AUTOSAR XML (schema 4-0-3)
package /Svc_NvM
  4 x impl type:
    NvM_BlockIdType: implementation-data-type=uint16
    NvM_RequestResultType: compu {0=NVM_REQ_OK, 1=NVM_REQ_NOT_OK, 2=NVM_REQ_PENDING, 3=NVM_REQ_INTEGRITY_FAILED, 4=NVM_REQ_BLOCK_SKIPPED, 5=NVM_REQ_NV_INVALIDATED, 6=NVM_REQ_CANCELED, 7=NVM_REQ_REDUNDANCY_FAILED, 8=NVM_REQ_RESTORED_FROM_ROM, 9=NVM_MAXVALUE}, implementation-data-type=uint8
    VoidPtr: category=DATA_REFERENCE, sw-pointer-target-props={target-category=VALUE, base-type=void}
    ConstVoidPtr: category=DATA_REFERENCE, sw-pointer-target-props={target-category=VALUE, base-type=void, sw-impl-policy=CONST}
  client server interface NvMNotifyInitBlock: is-service=true, service-kind=NON-VOLATILE-RAM-MANAGER
    operation InitBlock
  client server interface NvMNotifyJobFinished: is-service=true, service-kind=NON-VOLATILE-RAM-MANAGER
    operation JobFinished
      arg ServiceId: type=uint8, direction=IN
      arg JobResult: type=NvM_RequestResultType, direction=IN
  client server interface NvMService: is-service=true, service-kind=NON-VOLATILE-RAM-MANAGER
    7 x operation, all with possible-error=E_NOT_OK:
      GetErrorStatus
        arg RequestResultPtr: type=NvM_RequestResultType, direction=OUT
      ReadBlock
        arg Destination: type=VoidPtr, direction=IN
      WriteBlock
        arg Source: type=ConstVoidPtr, direction=IN
      RestoreBlockDefaults
        arg DstPtr: type=VoidPtr, direction=IN
      CancelJobs
      EraseNvBlock
      InvalidateNvBlock
    error E_NOT_OK: error-code=1
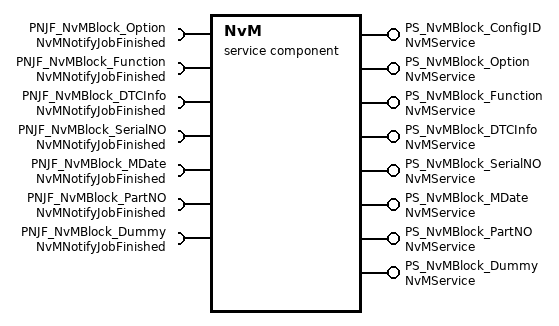
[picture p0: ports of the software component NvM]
  service sw component type NvM
    provide port PS_NvMBlock_ConfigID: provided-interface=NvMService
      provided-com-specs:
        operation=CancelJobs, queue-length=1
        operation=EraseNvBlock, queue-length=1
        operation=GetErrorStatus, queue-length=1
        operation=InvalidateNvBlock, queue-length=1
        operation=ReadBlock, queue-length=1
        operation=RestoreBlockDefaults, queue-length=1
        operation=WriteBlock, queue-length=1
    provide port PS_NvMBlock_Option: provided-interface=NvMService
      provided-com-specs:
        operation=CancelJobs, queue-length=1
        operation=EraseNvBlock, queue-length=1
        operation=GetErrorStatus, queue-length=1
        operation=InvalidateNvBlock, queue-length=1
        operation=ReadBlock, queue-length=1
        operation=RestoreBlockDefaults, queue-length=1
        operation=WriteBlock, queue-length=1
    require port PNJF_NvMBlock_Option: client-com-spec=JobFinished, required-interface=NvMNotifyJobFinished
    provide port PS_NvMBlock_Function: provided-interface=NvMService
      provided-com-specs:
        operation=CancelJobs, queue-length=1
        operation=EraseNvBlock, queue-length=1
        operation=GetErrorStatus, queue-length=1
        operation=InvalidateNvBlock, queue-length=1
        operation=ReadBlock, queue-length=1
        operation=RestoreBlockDefaults, queue-length=1
        operation=WriteBlock, queue-length=1
    require port PNJF_NvMBlock_Function: client-com-spec=JobFinished, required-interface=NvMNotifyJobFinished
    provide port PS_NvMBlock_DTCInfo: provided-interface=NvMService
      provided-com-specs:
        operation=CancelJobs, queue-length=1
        operation=EraseNvBlock, queue-length=1
        operation=GetErrorStatus, queue-length=1
        operation=InvalidateNvBlock, queue-length=1
        operation=ReadBlock, queue-length=1
        operation=RestoreBlockDefaults, queue-length=1
        operation=WriteBlock, queue-length=1
    require port PNJF_NvMBlock_DTCInfo: client-com-spec=JobFinished, required-interface=NvMNotifyJobFinished
    provide port PS_NvMBlock_SerialNO: provided-interface=NvMService
      provided-com-specs:
        operation=CancelJobs, queue-length=1
        operation=EraseNvBlock, queue-length=1
        operation=GetErrorStatus, queue-length=1
        operation=InvalidateNvBlock, queue-length=1
        operation=ReadBlock, queue-length=1
        operation=RestoreBlockDefaults, queue-length=1
        operation=WriteBlock, queue-length=1
    require port PNJF_NvMBlock_SerialNO: client-com-spec=JobFinished, required-interface=NvMNotifyJobFinished
    provide port PS_NvMBlock_MDate: provided-interface=NvMService
      provided-com-specs:
        operation=CancelJobs, queue-length=1
        operation=EraseNvBlock, queue-length=1
        operation=GetErrorStatus, queue-length=1
        operation=InvalidateNvBlock, queue-length=1
        operation=ReadBlock, queue-length=1
        operation=RestoreBlockDefaults, queue-length=1
        operation=WriteBlock, queue-length=1
    require port PNJF_NvMBlock_MDate: client-com-spec=JobFinished, required-interface=NvMNotifyJobFinished
    provide port PS_NvMBlock_PartNO: provided-interface=NvMService
      provided-com-specs:
        operation=CancelJobs, queue-length=1
        operation=EraseNvBlock, queue-length=1
        operation=GetErrorStatus, queue-length=1
        operation=InvalidateNvBlock, queue-length=1
        operation=ReadBlock, queue-length=1
        operation=RestoreBlockDefaults, queue-length=1
        operation=WriteBlock, queue-length=1
    require port PNJF_NvMBlock_PartNO: client-com-spec=JobFinished, required-interface=NvMNotifyJobFinished
    provide port PS_NvMBlock_Dummy: provided-interface=NvMService
      provided-com-specs:
        operation=CancelJobs, queue-length=1
        operation=EraseNvBlock, queue-length=1
        operation=GetErrorStatus, queue-length=1
        operation=InvalidateNvBlock, queue-length=1
        operation=ReadBlock, queue-length=1
        operation=RestoreBlockDefaults, queue-length=1
        operation=WriteBlock, queue-length=1
    require port PNJF_NvMBlock_Dummy: client-com-spec=JobFinished, required-interface=NvMNotifyJobFinished
    behavior IB_NvM: handle-termination-and-restart=NO-SUPPORT
      56 x operation invoked event:
        OperationInvokedEvent_PS_NvMBlock_ConfigID_CancelJobs: start-on-event=CancelJobs, operation=PS_NvMBlock_ConfigID.CancelJobs
        OperationInvokedEvent_PS_NvMBlock_ConfigID_EraseNvBlock: start-on-event=EraseNvBlock, operation=PS_NvMBlock_ConfigID.EraseNvBlock
        OperationInvokedEvent_PS_NvMBlock_ConfigID_GetErrorStatus: start-on-event=GetErrorStatus, operation=PS_NvMBlock_ConfigID.GetErrorStatus
        OperationInvokedEvent_PS_NvMBlock_ConfigID_InvalidateNvBlock: start-on-event=InvalidateNvBlock, operation=PS_NvMBlock_ConfigID.InvalidateNvBlock
        OperationInvokedEvent_PS_NvMBlock_ConfigID_ReadBlock: start-on-event=ReadBlock, operation=PS_NvMBlock_ConfigID.ReadBlock
        OperationInvokedEvent_PS_NvMBlock_ConfigID_RestoreBlockDefaults: start-on-event=RestoreBlockDefaults, operation=PS_NvMBlock_ConfigID.RestoreBlockDefaults
        OperationInvokedEvent_PS_NvMBlock_ConfigID_WriteBlock: start-on-event=WriteBlock, operation=PS_NvMBlock_ConfigID.WriteBlock
        OperationInvokedEvent_PS_NvMBlock_Option_CancelJobs: start-on-event=CancelJobs, operation=PS_NvMBlock_Option.CancelJobs
        OperationInvokedEvent_PS_NvMBlock_Option_EraseNvBlock: start-on-event=EraseNvBlock, operation=PS_NvMBlock_Option.EraseNvBlock
        OperationInvokedEvent_PS_NvMBlock_Option_GetErrorStatus: start-on-event=GetErrorStatus, operation=PS_NvMBlock_Option.GetErrorStatus
        OperationInvokedEvent_PS_NvMBlock_Option_InvalidateNvBlock: start-on-event=InvalidateNvBlock, operation=PS_NvMBlock_Option.InvalidateNvBlock
        OperationInvokedEvent_PS_NvMBlock_Option_ReadBlock: start-on-event=ReadBlock, operation=PS_NvMBlock_Option.ReadBlock
        OperationInvokedEvent_PS_NvMBlock_Option_RestoreBlockDefaults: start-on-event=RestoreBlockDefaults, operation=PS_NvMBlock_Option.RestoreBlockDefaults
        OperationInvokedEvent_PS_NvMBlock_Option_WriteBlock: start-on-event=WriteBlock, operation=PS_NvMBlock_Option.WriteBlock
        OperationInvokedEvent_PS_NvMBlock_Function_CancelJobs: start-on-event=CancelJobs, operation=PS_NvMBlock_Function.CancelJobs
        OperationInvokedEvent_PS_NvMBlock_Function_EraseNvBlock: start-on-event=EraseNvBlock, operation=PS_NvMBlock_Function.EraseNvBlock
        OperationInvokedEvent_PS_NvMBlock_Function_GetErrorStatus: start-on-event=GetErrorStatus, operation=PS_NvMBlock_Function.GetErrorStatus
        OperationInvokedEvent_PS_NvMBlock_Function_InvalidateNvBlock: start-on-event=InvalidateNvBlock, operation=PS_NvMBlock_Function.InvalidateNvBlock
        OperationInvokedEvent_PS_NvMBlock_Function_ReadBlock: start-on-event=ReadBlock, operation=PS_NvMBlock_Function.ReadBlock
        OperationInvokedEvent_PS_NvMBlock_Function_RestoreBlockDefaults: start-on-event=RestoreBlockDefaults, operation=PS_NvMBlock_Function.RestoreBlockDefaults
        OperationInvokedEvent_PS_NvMBlock_Function_WriteBlock: start-on-event=WriteBlock, operation=PS_NvMBlock_Function.WriteBlock
        OperationInvokedEvent_PS_NvMBlock_DTCInfo_CancelJobs: start-on-event=CancelJobs, operation=PS_NvMBlock_DTCInfo.CancelJobs
        OperationInvokedEvent_PS_NvMBlock_DTCInfo_EraseNvBlock: start-on-event=EraseNvBlock, operation=PS_NvMBlock_DTCInfo.EraseNvBlock
        OperationInvokedEvent_PS_NvMBlock_DTCInfo_GetErrorStatus: start-on-event=GetErrorStatus, operation=PS_NvMBlock_DTCInfo.GetErrorStatus
        OperationInvokedEvent_PS_NvMBlock_DTCInfo_InvalidateNvBlock: start-on-event=InvalidateNvBlock, operation=PS_NvMBlock_DTCInfo.InvalidateNvBlock
        OperationInvokedEvent_PS_NvMBlock_DTCInfo_ReadBlock: start-on-event=ReadBlock, operation=PS_NvMBlock_DTCInfo.ReadBlock
        OperationInvokedEvent_PS_NvMBlock_DTCInfo_RestoreBlockDefaults: start-on-event=RestoreBlockDefaults, operation=PS_NvMBlock_DTCInfo.RestoreBlockDefaults
        OperationInvokedEvent_PS_NvMBlock_DTCInfo_WriteBlock: start-on-event=WriteBlock, operation=PS_NvMBlock_DTCInfo.WriteBlock
        OperationInvokedEvent_PS_NvMBlock_SerialNO_CancelJobs: start-on-event=CancelJobs, operation=PS_NvMBlock_SerialNO.CancelJobs
        OperationInvokedEvent_PS_NvMBlock_SerialNO_EraseNvBlock: start-on-event=EraseNvBlock, operation=PS_NvMBlock_SerialNO.EraseNvBlock
        OperationInvokedEvent_PS_NvMBlock_SerialNO_GetErrorStatus: start-on-event=GetErrorStatus, operation=PS_NvMBlock_SerialNO.GetErrorStatus
        OperationInvokedEvent_PS_NvMBlock_SerialNO_InvalidateNvBlock: start-on-event=InvalidateNvBlock, operation=PS_NvMBlock_SerialNO.InvalidateNvBlock
        OperationInvokedEvent_PS_NvMBlock_SerialNO_ReadBlock: start-on-event=ReadBlock, operation=PS_NvMBlock_SerialNO.ReadBlock
        OperationInvokedEvent_PS_NvMBlock_SerialNO_RestoreBlockDefaults: start-on-event=RestoreBlockDefaults, operation=PS_NvMBlock_SerialNO.RestoreBlockDefaults
        OperationInvokedEvent_PS_NvMBlock_SerialNO_WriteBlock: start-on-event=WriteBlock, operation=PS_NvMBlock_SerialNO.WriteBlock
        OperationInvokedEvent_PS_NvMBlock_MDate_CancelJobs: start-on-event=CancelJobs, operation=PS_NvMBlock_MDate.CancelJobs
        OperationInvokedEvent_PS_NvMBlock_MDate_EraseNvBlock: start-on-event=EraseNvBlock, operation=PS_NvMBlock_MDate.EraseNvBlock
        OperationInvokedEvent_PS_NvMBlock_MDate_GetErrorStatus: start-on-event=GetErrorStatus, operation=PS_NvMBlock_MDate.GetErrorStatus
        OperationInvokedEvent_PS_NvMBlock_MDate_InvalidateNvBlock: start-on-event=InvalidateNvBlock, operation=PS_NvMBlock_MDate.InvalidateNvBlock
        OperationInvokedEvent_PS_NvMBlock_MDate_ReadBlock: start-on-event=ReadBlock, operation=PS_NvMBlock_MDate.ReadBlock
        OperationInvokedEvent_PS_NvMBlock_MDate_RestoreBlockDefaults: start-on-event=RestoreBlockDefaults, operation=PS_NvMBlock_MDate.RestoreBlockDefaults
        OperationInvokedEvent_PS_NvMBlock_MDate_WriteBlock: start-on-event=WriteBlock, operation=PS_NvMBlock_MDate.WriteBlock
        OperationInvokedEvent_PS_NvMBlock_PartNO_CancelJobs: start-on-event=CancelJobs, operation=PS_NvMBlock_PartNO.CancelJobs
        OperationInvokedEvent_PS_NvMBlock_PartNO_EraseNvBlock: start-on-event=EraseNvBlock, operation=PS_NvMBlock_PartNO.EraseNvBlock
        OperationInvokedEvent_PS_NvMBlock_PartNO_GetErrorStatus: start-on-event=GetErrorStatus, operation=PS_NvMBlock_PartNO.GetErrorStatus
        OperationInvokedEvent_PS_NvMBlock_PartNO_InvalidateNvBlock: start-on-event=InvalidateNvBlock, operation=PS_NvMBlock_PartNO.InvalidateNvBlock
        OperationInvokedEvent_PS_NvMBlock_PartNO_ReadBlock: start-on-event=ReadBlock, operation=PS_NvMBlock_PartNO.ReadBlock
        OperationInvokedEvent_PS_NvMBlock_PartNO_RestoreBlockDefaults: start-on-event=RestoreBlockDefaults, operation=PS_NvMBlock_PartNO.RestoreBlockDefaults
        OperationInvokedEvent_PS_NvMBlock_PartNO_WriteBlock: start-on-event=WriteBlock, operation=PS_NvMBlock_PartNO.WriteBlock
        OperationInvokedEvent_PS_NvMBlock_Dummy_CancelJobs: start-on-event=CancelJobs, operation=PS_NvMBlock_Dummy.CancelJobs
        OperationInvokedEvent_PS_NvMBlock_Dummy_EraseNvBlock: start-on-event=EraseNvBlock, operation=PS_NvMBlock_Dummy.EraseNvBlock
        OperationInvokedEvent_PS_NvMBlock_Dummy_GetErrorStatus: start-on-event=GetErrorStatus, operation=PS_NvMBlock_Dummy.GetErrorStatus
        OperationInvokedEvent_PS_NvMBlock_Dummy_InvalidateNvBlock: start-on-event=InvalidateNvBlock, operation=PS_NvMBlock_Dummy.InvalidateNvBlock
        OperationInvokedEvent_PS_NvMBlock_Dummy_ReadBlock: start-on-event=ReadBlock, operation=PS_NvMBlock_Dummy.ReadBlock
        OperationInvokedEvent_PS_NvMBlock_Dummy_RestoreBlockDefaults: start-on-event=RestoreBlockDefaults, operation=PS_NvMBlock_Dummy.RestoreBlockDefaults
        OperationInvokedEvent_PS_NvMBlock_Dummy_WriteBlock: start-on-event=WriteBlock, operation=PS_NvMBlock_Dummy.WriteBlock
      port-api-options:
        {enable-take-address=false, indirect-api=false, port-defined-argument-value{value=Block1:1, value-type=NvM_BlockIdType}, port=PS_NvMBlock_ConfigID}
        {enable-take-address=false, indirect-api=false, port-defined-argument-value{value=Block7:7, value-type=NvM_BlockIdType}, port=PS_NvMBlock_Option}
        {enable-take-address=false, indirect-api=false, port-defined-argument-value{value=Block8:8, value-type=NvM_BlockIdType}, port=PS_NvMBlock_Function}
        {enable-take-address=false, indirect-api=false, port-defined-argument-value{value=Block9:9, value-type=NvM_BlockIdType}, port=PS_NvMBlock_DTCInfo}
        {enable-take-address=false, indirect-api=false, port-defined-argument-value{value=Block10:10, value-type=NvM_BlockIdType}, port=PS_NvMBlock_SerialNO}
        {enable-take-address=false, indirect-api=false, port-defined-argument-value{value=Block11:11, value-type=NvM_BlockIdType}, port=PS_NvMBlock_MDate}
        {enable-take-address=false, indirect-api=false, port-defined-argument-value{value=Block12:12, value-type=NvM_BlockIdType}, port=PS_NvMBlock_PartNO}
        {enable-take-address=false, indirect-api=false, port-defined-argument-value{value=Block13:13, value-type=NvM_BlockIdType}, port=PS_NvMBlock_Dummy}
      8 x runnable:
        CancelJobs: runnable-entity-argument=symbol=BlockId, can-be-invoked-concurrently=true, symbol=NvM_CancelJobs
        EraseNvBlock: runnable-entity-argument=symbol=BlockId, can-be-invoked-concurrently=true, symbol=NvM_EraseNvBlock
        GetErrorStatus: arguments=[symbol=BlockId, symbol=RequestResultPtr], can-be-invoked-concurrently=true, symbol=NvM_GetErrorStatus
        InvalidateNvBlock: runnable-entity-argument=symbol=BlockId, can-be-invoked-concurrently=true, symbol=NvM_InvalidateNvBlock
        ReadBlock: arguments=[symbol=BlockId, symbol=NvM_DstPtr], can-be-invoked-concurrently=true, symbol=NvM_ReadBlock
        RestoreBlockDefaults: arguments=[symbol=BlockId, symbol=NvM_DstPtr], can-be-invoked-concurrently=true, symbol=NvM_RestoreBlockDefaults
        WriteBlock: arguments=[symbol=BlockId, symbol=NvM_SrcPtr], can-be-invoked-concurrently=true, symbol=NvM_WriteBlock
        MainFunction: symbol=NvM_MainFunction
          7 x sync call, all with timeout=0.0:
            SynchronousServerCallPoint_JF_NvMBlock_Option: operation=PNJF_NvMBlock_Option.JobFinished
            SynchronousServerCallPoint_JF_NvMBlock_Function: operation=PNJF_NvMBlock_Function.JobFinished
            SynchronousServerCallPoint_JF_NvMBlock_DTCInfo: operation=PNJF_NvMBlock_DTCInfo.JobFinished
            SynchronousServerCallPoint_JF_NvMBlock_SerialNO: operation=PNJF_NvMBlock_SerialNO.JobFinished
            SynchronousServerCallPoint_JF_NvMBlock_MDate: operation=PNJF_NvMBlock_MDate.JobFinished
            SynchronousServerCallPoint_JF_NvMBlock_PartNO: operation=PNJF_NvMBlock_PartNO.JobFinished
            SynchronousServerCallPoint_JF_NvMBlock_Dummy: operation=PNJF_NvMBlock_Dummy.JobFinished
  swc implementation SwcImplementation_NvM: programming-language=C, sw-version=1.5.3, swc-bsw-mapping=SwcBswMapping_NvM, vendor-id=59, behavior=IB_NvM
    code-descriptors:
      code Code: artifact-descriptors=autosar-engineering-object={short-label=NvM, category=SWOBJ}
    resource consumption ResourceConsumption
  swc bsw mapping SwcBswMapping_NvM: bsw-behavior=BswInternalBehavior_NvM, swc-bsw-runnable-mapping{bsw-entity=BswSE_NvM_MainFunction, swc-runnable=MainFunction}, swc-behavior=IB_NvM
